AUTOSAR XML (schema 00048)
package /HuaweiMDC/FunctionalSoftware/CameraLaneApplication/Execution
  executable CameraLaneExecutable
    root sw component prototype CameraLaneRootSwComponent: application-type=CameraLaneApplicationSwComponent
package /HuaweiMDC/FunctionalSoftware/CameraLaneApplication/SwComponent
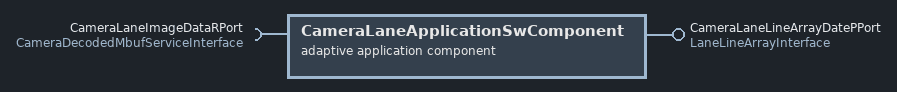
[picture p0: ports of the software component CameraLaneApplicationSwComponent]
  adaptive application sw component type CameraLaneApplicationSwComponent
    require port CameraLaneImageDataRPort: required-interface=CameraDecodedMbufServiceInterface
    provide port CameraLaneLineArrayDatePPort: provided-interface=LaneLineArrayInterface
